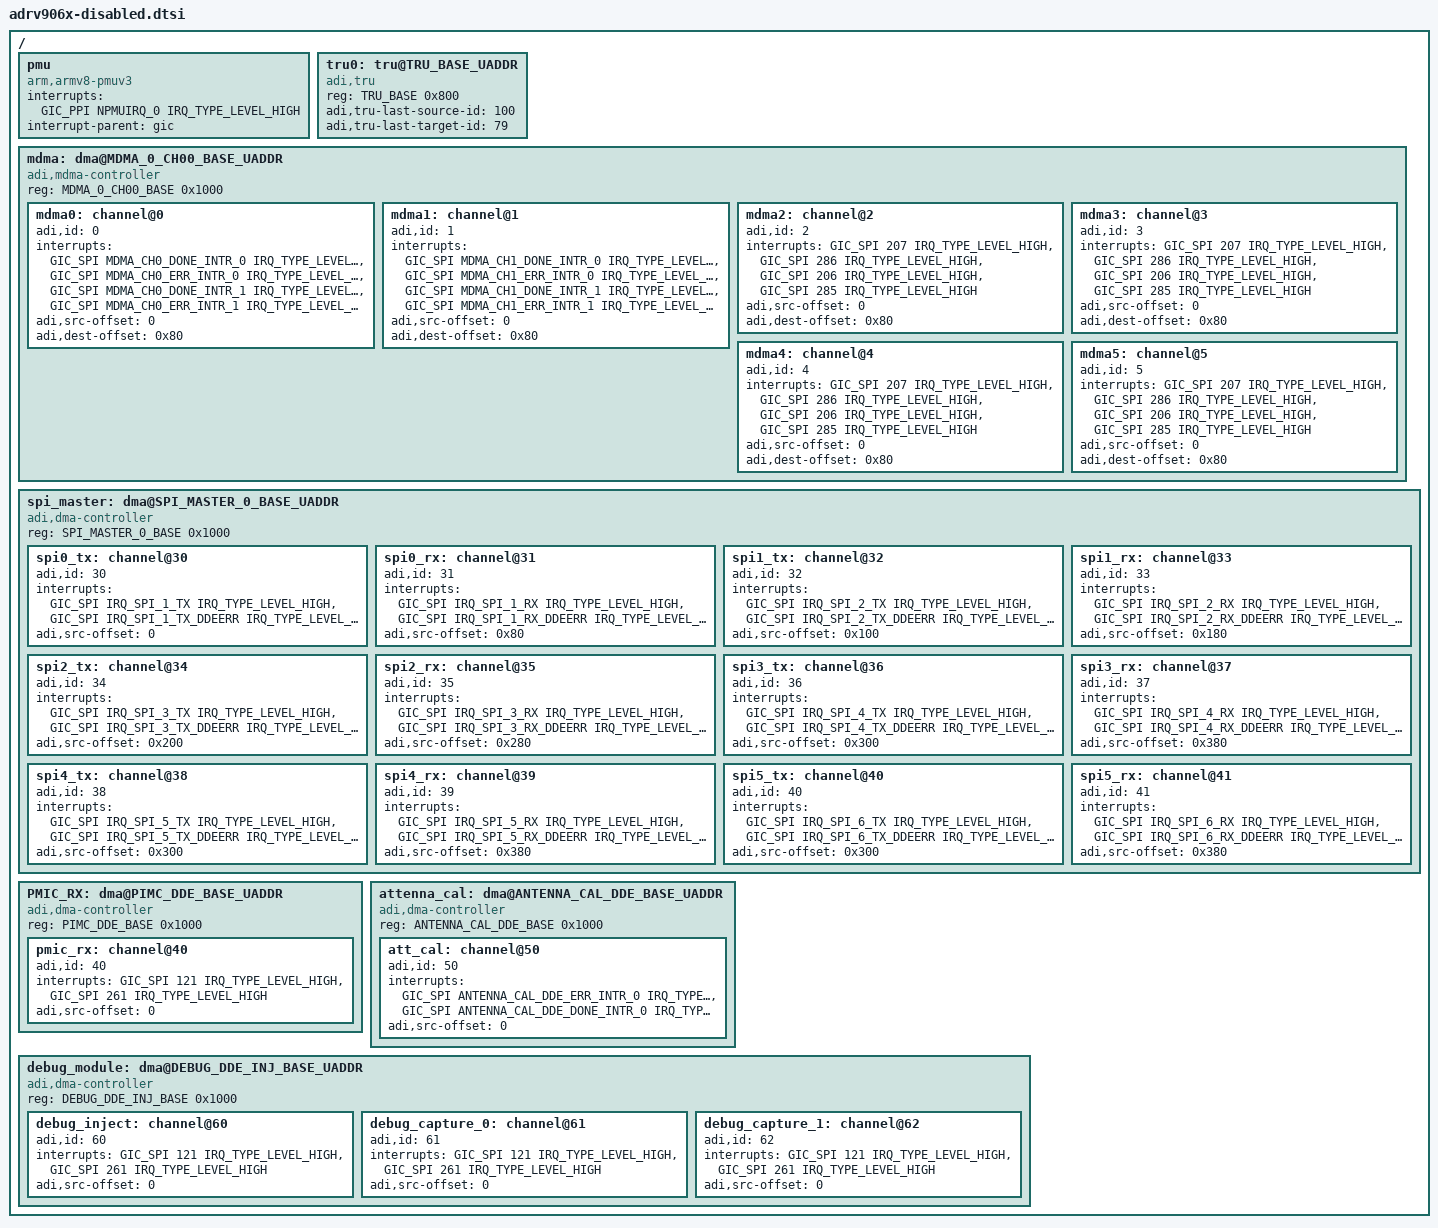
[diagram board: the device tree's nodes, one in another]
// SPDX-License-Identifier: GPL-2.0
/*
 * Copyright (c) 2023, Analog Devices Incorporated, All Rights Reserved
 */

/dts-v1/;

/* Sandbox for all adrv906x devices that are not ready to be compiled in or enabled.
 *
 * TODO: Move these into adrv906x.dtsi as they become ready, and eventually remove
 * this file.
 */

/ {
	pmu {
		compatible = "arm,armv8-pmuv3";
		interrupts = <GIC_PPI NPMUIRQ_0 IRQ_TYPE_LEVEL_HIGH>;
		interrupt-parent = <&gic>;
	};

	tru0: tru@TRU_BASE_UADDR {
		compatible = "adi,tru";
		reg = <TRU_BASE 0x800>;
		/* TODO replace 100 with actual last trigger source ID */
		adi,tru-last-source-id = <100>;
		adi,tru-last-target-id = <79>;
		/* each connection is <source target> */
		/*
		adi,tru-connections-preset = <1 2>,
				<25 32>,
				<3 4>;
		adi,tru-connections-preset-locked;
		*/
	};

	/* TODO: enable blocks below and test when avail*/
	/* memory to memory DMA */
	mdma: dma@MDMA_0_CH00_BASE_UADDR {
		compatible = "adi,mdma-controller";
		reg = <MDMA_0_CH00_BASE 0x1000>;
		status = "okay";

		mdma0: channel@0{
			adi,id = <0>;
			// The destination interrupts are used for primary complete detection
			interrupts = <GIC_SPI MDMA_CH0_DONE_INTR_0 IRQ_TYPE_LEVEL_HIGH>,
						 <GIC_SPI MDMA_CH0_ERR_INTR_0 IRQ_TYPE_LEVEL_HIGH>,
						 <GIC_SPI MDMA_CH0_DONE_INTR_1 IRQ_TYPE_LEVEL_HIGH>,
						 <GIC_SPI MDMA_CH0_ERR_INTR_1 IRQ_TYPE_LEVEL_HIGH>;
			interrupt-names = "complete", "error", "complete2", "error2";
			adi,src-offset = <0>;
			adi,dest-offset = <0x80>;
		};
		mdma1: channel@1{
			adi,id = <1>;
			// The destination interrupts are used for primary complete detection
			interrupts = <GIC_SPI MDMA_CH1_DONE_INTR_0 IRQ_TYPE_LEVEL_HIGH>,
						 <GIC_SPI MDMA_CH1_ERR_INTR_0 IRQ_TYPE_LEVEL_HIGH>,
						 <GIC_SPI MDMA_CH1_DONE_INTR_1 IRQ_TYPE_LEVEL_HIGH>,
						 <GIC_SPI MDMA_CH1_ERR_INTR_1 IRQ_TYPE_LEVEL_HIGH>;
			interrupt-names = "complete", "error", "complete2", "error2";
			adi,src-offset = <0>;
			adi,dest-offset = <0x80>;
		};
		mdma2: channel@2{
			adi,id = <2>;
			// The destination interrupts are used for primary complete detection
			interrupts = <GIC_SPI 207 IRQ_TYPE_LEVEL_HIGH>,
						 <GIC_SPI 286 IRQ_TYPE_LEVEL_HIGH>,
						 <GIC_SPI 206 IRQ_TYPE_LEVEL_HIGH>,
						 <GIC_SPI 285 IRQ_TYPE_LEVEL_HIGH>;
			interrupt-names = "complete", "error", "complete2", "error2";
			adi,src-offset = <0>;
			adi,dest-offset = <0x80>;
		};
		mdma3: channel@3{
			adi,id = <3>;
			// The destination interrupts are used for primary complete detection
			interrupts = <GIC_SPI 207 IRQ_TYPE_LEVEL_HIGH>,
						 <GIC_SPI 286 IRQ_TYPE_LEVEL_HIGH>,
						 <GIC_SPI 206 IRQ_TYPE_LEVEL_HIGH>,
						 <GIC_SPI 285 IRQ_TYPE_LEVEL_HIGH>;
			interrupt-names = "complete", "error", "complete2", "error2";
			adi,src-offset = <0>;
			adi,dest-offset = <0x80>;
		};
		mdma4: channel@4{
			adi,id = <4>;
			// The destination interrupts are used for primary complete detection
			interrupts = <GIC_SPI 207 IRQ_TYPE_LEVEL_HIGH>,
						 <GIC_SPI 286 IRQ_TYPE_LEVEL_HIGH>,
						 <GIC_SPI 206 IRQ_TYPE_LEVEL_HIGH>,
						 <GIC_SPI 285 IRQ_TYPE_LEVEL_HIGH>;
			interrupt-names = "complete", "error", "complete2", "error2";
			adi,src-offset = <0>;
			adi,dest-offset = <0x80>;
		};
		mdma5: channel@5{
			adi,id = <5>;
			// The destination interrupts are used for primary complete detection
			interrupts = <GIC_SPI 207 IRQ_TYPE_LEVEL_HIGH>,
						 <GIC_SPI 286 IRQ_TYPE_LEVEL_HIGH>,
						 <GIC_SPI 206 IRQ_TYPE_LEVEL_HIGH>,
						 <GIC_SPI 285 IRQ_TYPE_LEVEL_HIGH>;
			interrupt-names = "complete", "error", "complete2", "error2";
			adi,src-offset = <0>;
			adi,dest-offset = <0x80>;
		};
	};

	/* spi master */
	spi_master: dma@SPI_MASTER_0_BASE_UADDR {
		compatible = "adi,dma-controller";
		reg = <SPI_MASTER_0_BASE 0x1000>;
		status = "okay";
		#dma-cells = <1>;

		spi0_tx: channel@30 {
			adi,id = <30>;
			interrupts = <GIC_SPI IRQ_SPI_1_TX IRQ_TYPE_LEVEL_HIGH>,
						 <GIC_SPI IRQ_SPI_1_TX_DDEERR IRQ_TYPE_LEVEL_HIGH>;
			interrupt-names = "complete", "error";
			adi,src-offset = <0>;
		};

		spi0_rx: channel@31 {
			adi,id = <31>;
			interrupts = <GIC_SPI IRQ_SPI_1_RX IRQ_TYPE_LEVEL_HIGH>,
						 <GIC_SPI IRQ_SPI_1_RX_DDEERR IRQ_TYPE_LEVEL_HIGH>;
			interrupt-names = "complete", "error";
			adi,src-offset = <0x80>;
		};

		spi1_tx: channel@32 {
			adi,id = <32>;
			interrupts = <GIC_SPI IRQ_SPI_2_TX IRQ_TYPE_LEVEL_HIGH>,
						 <GIC_SPI IRQ_SPI_2_TX_DDEERR IRQ_TYPE_LEVEL_HIGH>;
			interrupt-names = "complete", "error";
			adi,src-offset = <0x100>;
		};

		spi1_rx: channel@33 {
			adi,id = <33>;
			interrupts = <GIC_SPI IRQ_SPI_2_RX IRQ_TYPE_LEVEL_HIGH>,
						 <GIC_SPI IRQ_SPI_2_RX_DDEERR IRQ_TYPE_LEVEL_HIGH>;
			interrupt-names = "complete", "error";
			adi,src-offset = <0x180>;
		};

		spi2_tx: channel@34 {
			adi,id = <34>;
			interrupts = <GIC_SPI IRQ_SPI_3_TX IRQ_TYPE_LEVEL_HIGH>,
						 <GIC_SPI IRQ_SPI_3_TX_DDEERR IRQ_TYPE_LEVEL_HIGH>;
			interrupt-names = "complete", "error";
			adi,src-offset = <0x200>;
		};

		spi2_rx: channel@35 {
			adi,id = <35>;
			interrupts = <GIC_SPI IRQ_SPI_3_RX IRQ_TYPE_LEVEL_HIGH>,
						 <GIC_SPI IRQ_SPI_3_RX_DDEERR IRQ_TYPE_LEVEL_HIGH>;
			interrupt-names = "complete", "error";
			adi,src-offset = <0x280>;
		};

		spi3_tx: channel@36 {
			adi,id = <36>;
			interrupts = <GIC_SPI IRQ_SPI_4_TX IRQ_TYPE_LEVEL_HIGH>,
						 <GIC_SPI IRQ_SPI_4_TX_DDEERR IRQ_TYPE_LEVEL_HIGH>;
			interrupt-names = "complete", "error";
			adi,src-offset = <0x300>;
		};

		spi3_rx: channel@37 {
			adi,id = <37>;
			interrupts = <GIC_SPI IRQ_SPI_4_RX IRQ_TYPE_LEVEL_HIGH>,
						 <GIC_SPI IRQ_SPI_4_RX_DDEERR IRQ_TYPE_LEVEL_HIGH>;
			interrupt-names = "complete", "error";
			adi,src-offset = <0x380>;
		};

		spi4_tx: channel@38 {
			adi,id = <38>;
			interrupts = <GIC_SPI IRQ_SPI_5_TX IRQ_TYPE_LEVEL_HIGH>,
						 <GIC_SPI IRQ_SPI_5_TX_DDEERR IRQ_TYPE_LEVEL_HIGH>;
			interrupt-names = "complete", "error";
			adi,src-offset = <0x300>;
		};

		spi4_rx: channel@39 {
			adi,id = <39>;
			interrupts = <GIC_SPI IRQ_SPI_5_RX IRQ_TYPE_LEVEL_HIGH>,
						 <GIC_SPI IRQ_SPI_5_RX_DDEERR IRQ_TYPE_LEVEL_HIGH>;
			interrupt-names = "complete", "error";
			adi,src-offset = <0x380>;
		};
		spi5_tx: channel@40 {
			adi,id = <40>;
			interrupts = <GIC_SPI IRQ_SPI_6_TX IRQ_TYPE_LEVEL_HIGH>,
						 <GIC_SPI IRQ_SPI_6_TX_DDEERR IRQ_TYPE_LEVEL_HIGH>;
			interrupt-names = "complete", "error";
			adi,src-offset = <0x300>;
		};

		spi5_rx: channel@41 {
			adi,id = <41>;
			interrupts = <GIC_SPI IRQ_SPI_6_RX IRQ_TYPE_LEVEL_HIGH>,
						 <GIC_SPI IRQ_SPI_6_RX_DDEERR IRQ_TYPE_LEVEL_HIGH>;
			interrupt-names = "complete", "error";
			adi,src-offset = <0x380>;
		};

	};

	/* PMIC */
	PMIC_RX: dma@PIMC_DDE_BASE_UADDR {
		compatible = "adi,dma-controller";
		reg = <PIMC_DDE_BASE 0x1000>;
		status = "okay";
		#dma-cells = <1>;

		pmic_rx: channel@40 {
			adi,id = <40>;
			interrupts = <GIC_SPI 121 IRQ_TYPE_LEVEL_HIGH>,
						 <GIC_SPI 261 IRQ_TYPE_LEVEL_HIGH>;
			interrupt-names = "complete", "error";
			adi,src-offset = <0>;
		};
	};

	/* anttena calibration */
	attenna_cal: dma@ANTENNA_CAL_DDE_BASE_UADDR {
		compatible = "adi,dma-controller";
		reg = <ANTENNA_CAL_DDE_BASE 0x1000>;
		status = "okay";
		#dma-cells = <1>;

		att_cal: channel@50 {
			adi,id = <50>;
			interrupts = <GIC_SPI ANTENNA_CAL_DDE_ERR_INTR_0 IRQ_TYPE_LEVEL_HIGH>,
						 <GIC_SPI ANTENNA_CAL_DDE_DONE_INTR_0 IRQ_TYPE_LEVEL_HIGH>;
			interrupt-names = "complete", "error";
			adi,src-offset = <0>;
		};
	};

	/* debug inject */
	debug_module: dma@DEBUG_DDE_INJ_BASE_UADDR {
		compatible = "adi,dma-controller";
		reg = <DEBUG_DDE_INJ_BASE 0x1000>;
		status = "okay";
		#dma-cells = <1>;

		debug_inject: channel@60 {
			adi,id = <60>;
			interrupts = <GIC_SPI 121 IRQ_TYPE_LEVEL_HIGH>,
						 <GIC_SPI 261 IRQ_TYPE_LEVEL_HIGH>;
			interrupt-names = "complete", "error";
			adi,src-offset = <0>;
		};
		debug_capture_0: channel@61 {
			adi,id = <61>;
			interrupts = <GIC_SPI 121 IRQ_TYPE_LEVEL_HIGH>,
						 <GIC_SPI 261 IRQ_TYPE_LEVEL_HIGH>;
			interrupt-names = "complete", "error";
			adi,src-offset = <0>;
		};
		debug_capture_1: channel@62 {
			adi,id = <62>;
			interrupts = <GIC_SPI 121 IRQ_TYPE_LEVEL_HIGH>,
						 <GIC_SPI 261 IRQ_TYPE_LEVEL_HIGH>;
			interrupt-names = "complete", "error";
			adi,src-offset = <0>;
		};

	};
};
